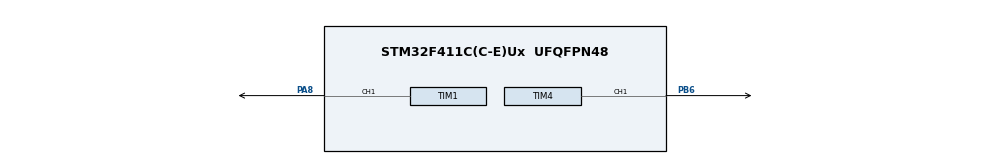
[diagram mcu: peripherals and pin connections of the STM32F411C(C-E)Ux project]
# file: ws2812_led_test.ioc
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Dma.Request0=TIM1_CH1
Dma.Request1=TIM4_CH1
Dma.TIM1_CH1.0.Direction=DMA_MEMORY_TO_PERIPH
Dma.TIM1_CH1.0.FIFOMode=DMA_FIFOMODE_DISABLE
Dma.TIM1_CH1.0.Instance=DMA2_Stream1
Dma.TIM1_CH1.0.MemDataAlignment=DMA_MDATAALIGN_HALFWORD
Dma.TIM1_CH1.0.MemInc=DMA_MINC_ENABLE
Dma.TIM1_CH1.0.Mode=DMA_NORMAL
Dma.TIM1_CH1.0.PeriphDataAlignment=DMA_PDATAALIGN_HALFWORD
Dma.TIM1_CH1.0.PeriphInc=DMA_PINC_DISABLE
Dma.TIM1_CH1.0.Priority=DMA_PRIORITY_LOW
Dma.TIM4_CH1.1.Direction=DMA_MEMORY_TO_PERIPH
Dma.TIM4_CH1.1.FIFOMode=DMA_FIFOMODE_DISABLE
Dma.TIM4_CH1.1.Instance=DMA1_Stream0
Dma.TIM4_CH1.1.MemDataAlignment=DMA_MDATAALIGN_HALFWORD
Dma.TIM4_CH1.1.MemInc=DMA_MINC_ENABLE
Dma.TIM4_CH1.1.Mode=DMA_NORMAL
Dma.TIM4_CH1.1.PeriphDataAlignment=DMA_PDATAALIGN_HALFWORD
Dma.TIM4_CH1.1.PeriphInc=DMA_PINC_DISABLE
Dma.TIM4_CH1.1.Priority=DMA_PRIORITY_LOW
Mcu.Family=STM32F4
Mcu.Name=STM32F411C(C-E)Ux
Mcu.Package=UFQFPN48
NVIC.DMA1_Stream0_IRQn=true\:0\:0\:false\:false\:true\:false\:true
NVIC.DMA2_Stream1_IRQn=true\:0\:0\:false\:false\:true\:false\:true
NVIC.PriorityGroup=NVIC_PRIORITYGROUP_4
PA13.Mode=Serial_Wire
PA13.Signal=SYS_JTMS-SWDIO
PA14.Mode=Serial_Wire
PA14.Signal=SYS_JTCK-SWCLK
PA8.Signal=S_TIM1_CH1
PB6.Signal=S_TIM4_CH1
PH0\ -\ OSC_IN.Mode=HSE-External-Oscillator
PH0\ -\ OSC_IN.Signal=RCC_OSC_IN
PH1\ -\ OSC_OUT.Mode=HSE-External-Oscillator
PH1\ -\ OSC_OUT.Signal=RCC_OSC_OUT
ProjectManager.HeapSize=0x200
ProjectManager.StackSize=0x400
ProjectManager.TargetToolchain=STM32CubeIDE
RCC.48MHZClocksFreq_Value=50000000
RCC.AHBFreq_Value=100000000
RCC.APB1CLKDivider=RCC_HCLK_DIV2
RCC.APB1Freq_Value=50000000
RCC.APB1TimFreq_Value=100000000
RCC.APB2Freq_Value=100000000
RCC.APB2TimFreq_Value=100000000
RCC.CortexFreq_Value=100000000
RCC.HCLKFreq_Value=100000000
RCC.HSE_VALUE=25000000
RCC.HSI_VALUE=16000000
RCC.LSE_VALUE=32768
RCC.PLLM=12
RCC.PLLN=96
RCC.PLLSourceVirtual=RCC_PLLSOURCE_HSE
RCC.SYSCLKFreq_VALUE=100000000
RCC.SYSCLKSource=RCC_SYSCLKSOURCE_PLLCLK
RCC.VCOOutputFreq_Value=200000000
SH.S_TIM1_CH1.0=TIM1_CH1,PWM Generation1 CH1
SH.S_TIM4_CH1.0=TIM4_CH1,PWM Generation1 CH1
TIM1.AutoReloadPreload=TIM_AUTORELOAD_PRELOAD_DISABLE
TIM1.Channel-PWM\ Generation1\ CH1=TIM_CHANNEL_1
TIM1.Period=125-1
TIM1.Pulse-PWM\ Generation1\ CH1=0
TIM4.Channel-PWM\ Generation1\ CH1=TIM_CHANNEL_1
TIM4.Period=125-1
VP_TIM1_VS_ClockSourceINT.Mode=Internal
VP_TIM4_VS_ClockSourceINT.Mode=Internal
board=custom

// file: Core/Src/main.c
/* USER CODE BEGIN Header */
/**
  ******************************************************************************
  * @file           : main.c
  * @brief          : Main program body
  ******************************************************************************
  * @attention
  *
  * <h2><center>&copy; Copyright (c) 2021 STMicroelectronics.
  * All rights reserved.</center></h2>
  *
  * This software component is licensed by ST under BSD 3-Clause license,
  * the "License"; You may not use this file except in compliance with the
  * License. You may obtain a copy of the License at:
  *                        opensource.org/licenses/BSD-3-Clause
  *
  ******************************************************************************
  */
/* USER CODE END Header */
#include "main.h"
#include "dma.h"
#include "tim.h"
#include "gpio.h"

/* USER CODE BEGIN Includes */
#include "ws2812_led.h"
/* USER CODE END Includes */

void SystemClock_Config(void);

int main(void)
{

  /* MCU Configuration--------------------------------------------------------*/

  /* Reset of all peripherals, Initializes the Flash interface and the Systick. */

  LL_APB2_GRP1_EnableClock(LL_APB2_GRP1_PERIPH_SYSCFG);
  LL_APB1_GRP1_EnableClock(LL_APB1_GRP1_PERIPH_PWR);

  NVIC_SetPriorityGrouping(NVIC_PRIORITYGROUP_4);

  /* System interrupt init*/
  /* SysTick_IRQn interrupt configuration */
  NVIC_SetPriority(SysTick_IRQn, NVIC_EncodePriority(NVIC_GetPriorityGrouping(),15, 0));

  /* Configure the system clock */
  SystemClock_Config();

  /* Initialize all configured peripherals */
  MX_GPIO_Init();
  MX_TIM1_Init();
  MX_DMA_Init();
  MX_TIM4_Init();
  /* USER CODE BEGIN 2 */
  ws2812_init(&WS2812_STRIP1);
//  ws2812_send(200,10,60);
  /* USER CODE END 2 */

  /* Infinite loop */
  /* USER CODE BEGIN WHILE */
  while (1)
  {
	  ws2812_updateString(&WS2812_STRIP1);
    /* USER CODE END WHILE */

  }
}

void SystemClock_Config(void)
{
  LL_FLASH_SetLatency(LL_FLASH_LATENCY_3);
  while(LL_FLASH_GetLatency()!= LL_FLASH_LATENCY_3)
  {
  }
  LL_PWR_SetRegulVoltageScaling(LL_PWR_REGU_VOLTAGE_SCALE1);
  LL_RCC_HSE_Enable();

   /* Wait till HSE is ready */
  while(LL_RCC_HSE_IsReady() != 1)
  {

  }
  LL_RCC_PLL_ConfigDomain_SYS(LL_RCC_PLLSOURCE_HSE, LL_RCC_PLLM_DIV_12, 96, LL_RCC_PLLP_DIV_2);
  LL_RCC_PLL_Enable();

   /* Wait till PLL is ready */
  while(LL_RCC_PLL_IsReady() != 1)
  {

  }
  LL_RCC_SetAHBPrescaler(LL_RCC_SYSCLK_DIV_1);
  LL_RCC_SetAPB1Prescaler(LL_RCC_APB1_DIV_2);
  LL_RCC_SetAPB2Prescaler(LL_RCC_APB2_DIV_1);
  LL_RCC_SetSysClkSource(LL_RCC_SYS_CLKSOURCE_PLL);

   /* Wait till System clock is ready */
  while(LL_RCC_GetSysClkSource() != LL_RCC_SYS_CLKSOURCE_STATUS_PLL)
  {

  }
  LL_Init1msTick(100000000);
  LL_SetSystemCoreClock(100000000);
  LL_RCC_SetTIMPrescaler(LL_RCC_TIM_PRESCALER_TWICE);
}

void Error_Handler(void)
{
  __disable_irq();
  while (1)
  {
  }
}

/************************ (C) COPYRIGHT STMicroelectronics *****END OF FILE****/
